AUTOSAR XML (schema 4-1-3)
standard types defined: boolean, sint8, uint16, uint32, uint8, boolean_CompuMethod, boolean_DataConstr, sint8_DataConstr, uint16_DataConstr, uint32_DataConstr, uint8_DataConstr, sint16
package /ComponentTypes/DataTypeMappingSets
  data type mapping set DTMS_CabinT_DD
    data-type-maps:
      application-data-type=Appl_CabinT_tTrfReSnsr_CUR, implementation-data-type=CabinT_tTrfReSnsr_CUR_Type
      application-data-type=Appl_CabinT_tTrfSnsr_CUR, implementation-data-type=CabinT_tTrfSnsr_CUR_Type
      application-data-type=T_q0p1_o273p14_DegC_s16, implementation-data-type=sint16
      application-data-type=U_q1_mV_u16, implementation-data-type=ImplementationDataTypes/uint16
package /MICROSAR/Dem_swc/DataTypes
  5 x impl type:
    Dem_DebounceResetStatusType: compu {0=DEM_DEBOUNCE_STATUS_FREEZE, 1=DEM_DEBOUNCE_STATUS_RESET}, range raw 0..255, implementation-data-type=ImplementationDataTypes/uint8
    Dem_DTCFormatType: compu {0=DEM_DTC_FORMAT_OBD, 1=DEM_DTC_FORMAT_UDS, 2=DEM_DTC_FORMAT_J1939}, range raw 0..2, implementation-data-type=ImplementationDataTypes/uint8
    Dem_EventStatusType:
      compu {0=DEM_EVENT_STATUS_PASSED, 1=DEM_EVENT_STATUS_FAILED, 2=DEM_EVENT_STATUS_PREPASSED, 3=DEM_EVENT_STATUS_PREFAILED, 4=DEM_EVENT_STATUS_FDC_THRESHOLD_REACHED, 5=DEM_EVENT_STATUS_PASSED_CONDITIONS_NOT_FULFILLED, 6=DEM_EVENT_STATUS_FAILED_CONDITIONS_NOT_FULFILLED, 7=DEM_EVENT_STATUS_PREPASSED_CONDITIONS_NOT_FULFILLED, 8=DEM_EVENT_STATUS_PREFAILED_CONDITIONS_NOT_FULFILLED}
      range raw 0..255
      implementation-data-type=ImplementationDataTypes/uint8
    Dem_MaxDataValueType: category=ARRAY, sw-calibration-access=READ-ONLY
      element Dem_MaxDataValueTypeElement: array-size=40, array-size-semantics=FIXED-SIZE, implementation-data-type=ImplementationDataTypes/uint8
    Dem_UdsStatusByteType:
      compu {mask 1: 1=DEM_UDS_STATUS_TF (bit 0: TestFailed), mask 2: 2=DEM_UDS_STATUS_TFTOC (bit 1: TestFailedThisOperationCycle), mask 4: 4=DEM_UDS_STATUS_PDTC (bit 2: PendingDTC), mask 8: 8=DEM_UDS_STATUS_CDTC (bit 3: ConfirmedDTC), mask 16: 16=DEM_UDS_STATUS_TNCSLC (bit 4: TestNotCompletedSinceLastClear), mask 32: 32=DEM_UDS_STATUS_TFSLC (bit 5: TestFailedSinceLastClear), mask 64: 64=DEM_UDS_STATUS_TNCTOC (bit 6: TestNotCompletedThisOperationCycle), mask 128: 128=DEM_UDS_STATUS_WIR (bit 7: WarningIndicatorRequested)}
      range raw 0..255
      implementation-data-type=ImplementationDataTypes/uint8
package /MICROSAR/Dem_swc/Interfaces
  client server interface DiagnosticMonitor: is-service=true, service-kind=DIAGNOSTIC-EVENT-MANAGER
    11 x operation:
      GetDTCOfEvent: possible-error=[DEM_E_NO_DTC_AVAILABLE, DiagnosticMonitor/E_NOT_OK]
        arg DTCFormat: type=Dem_DTCFormatType, direction=IN, server-argument-impl-policy=USE-ARGUMENT-TYPE
        arg DTCOfEvent: type=uint32, direction=OUT, server-argument-impl-policy=USE-ARGUMENT-TYPE
      GetEventExtendedDataRecordEx: possible-error=[DEM_BUFFER_TOO_SMALL, DEM_NO_SUCH_ELEMENT, DiagnosticMonitor/E_NOT_OK]
        arg RecordNumber: type=ImplementationDataTypes/uint8, direction=IN, server-argument-impl-policy=USE-ARGUMENT-TYPE
        arg DestBuffer: type=Dem_MaxDataValueType, direction=OUT, server-argument-impl-policy=USE-ARGUMENT-TYPE
        arg BufSize: type=ImplementationDataTypes/uint16, direction=INOUT, server-argument-impl-policy=USE-ARGUMENT-TYPE
      GetEventFailed: possible-error=DiagnosticMonitor/E_NOT_OK
        arg EventFailed: type=ImplementationDataTypes/boolean, direction=OUT, server-argument-impl-policy=USE-ARGUMENT-TYPE
      GetEventFreezeFrameDataEx: possible-error=[DEM_BUFFER_TOO_SMALL, DEM_NO_SUCH_ELEMENT, DiagnosticMonitor/E_NOT_OK]
        4 x arg, all with server-argument-impl-policy=USE-ARGUMENT-TYPE:
          RecordNumber: type=ImplementationDataTypes/uint8, direction=IN
          DataId: type=ImplementationDataTypes/uint16, direction=IN
          DestBuffer: type=Dem_MaxDataValueType, direction=OUT
          BufSize: type=ImplementationDataTypes/uint16, direction=INOUT
      GetEventStatus: possible-error=DiagnosticMonitor/E_NOT_OK
        arg UDSStatusByte: type=Dem_UdsStatusByteType, direction=OUT, server-argument-impl-policy=USE-ARGUMENT-TYPE
      GetEventTested: possible-error=DiagnosticMonitor/E_NOT_OK
        arg EventTested: type=ImplementationDataTypes/boolean, direction=OUT, server-argument-impl-policy=USE-ARGUMENT-TYPE
      GetEventUdsStatus: possible-error=DiagnosticMonitor/E_NOT_OK
        arg UDSStatusByte: type=Dem_UdsStatusByteType, direction=OUT, server-argument-impl-policy=USE-ARGUMENT-TYPE
      GetFaultDetectionCounter: possible-error=[DEM_E_NO_FDC_AVAILABLE, DiagnosticMonitor/E_NOT_OK]
        arg FaultDetectionCounter: type=sint8, direction=OUT, server-argument-impl-policy=USE-ARGUMENT-TYPE
      ResetEventDebounceStatus: possible-error=DiagnosticMonitor/E_NOT_OK
        arg DebounceResetStatus: type=Dem_DebounceResetStatusType, direction=IN, server-argument-impl-policy=USE-ARGUMENT-TYPE
      ResetEventStatus: possible-error=DiagnosticMonitor/E_NOT_OK
      SetEventStatus: possible-error=DiagnosticMonitor/E_NOT_OK
        arg EventStatus: type=Dem_EventStatusType, direction=IN, server-argument-impl-policy=USE-ARGUMENT-TYPE
    5 x error:
      DEM_BUFFER_TOO_SMALL: error-code=21
      DEM_E_NO_DTC_AVAILABLE: error-code=10
      DEM_E_NO_FDC_AVAILABLE: error-code=14
      DEM_NO_SUCH_ELEMENT: error-code=48
      E_NOT_OK: error-code=1
package /UAES/ASW/ApplicationDataTypes
  4 x app type, all with sw-calibration-access=READ-WRITE:
    Appl_CabinT_tTrfReSnsr_CUR: category=CURVE, sw-calprm-axis-set={sw-axis-index=1, category=COM_AXIS, sw-axis-individual={compu {phys=raw for raw -INF..INF; unit mV}, sw-max-axis-points=30, sw-min-axis-points=30, range phys 0..65535, raw 0..65535}}, compu {phys=raw*0.1-273.14 for raw -INF..INF; unit DegC}, range raw -32768..32767
    Appl_CabinT_tTrfSnsr_CUR: category=CURVE, sw-calprm-axis-set={sw-axis-index=1, category=COM_AXIS, sw-axis-individual={compu {phys=raw for raw -INF..INF; unit mV}, sw-max-axis-points=30, sw-min-axis-points=30, range phys 0..65535, raw 0..65535}}, compu {phys=raw*0.1-273.14 for raw -INF..INF; unit DegC}, range raw -32768..32767
    T_q0p1_o273p14_DegC_s16: category=VALUE, compu {phys=raw*0.1-273.14 for raw -INF..INF; unit DegC}, range raw -32768..32767
    U_q1_mV_u16: category=VALUE, compu {phys=raw for raw -INF..INF; unit mV}, range phys 0..65535, raw 0..65535
package /UAES/ASW/CompuMethods
  compu method CM_boolean: 0=FALSE, 1=TRUE
package /UAES/ASW/DataConstrs
  range DC_boolean: raw 0..1
  range DC_sint16: raw -32768..32767
  range DC_uint16: phys 0..6553.5, raw 0..65535
  range DC_uint8: raw 0..255
package /UAES/ASW/ImplementationDataTypes
  6 x impl type:
    CabinT_tTrfReSnsr_CUR_Type: category=STRUCTURE
      element N1: implementation-data-type=ImplementationDataTypes/uint16
      element BP1: implementation-data-type=rt_Array_U_q1_mV_u16_30
      element Table: implementation-data-type=rt_Array_T_q0p1_o273p14_DegC_s16_30
    CabinT_tTrfSnsr_CUR_Type: category=STRUCTURE
      element N1: implementation-data-type=ImplementationDataTypes/uint16
      element BP1: implementation-data-type=rt_Array_U_q1_mV_u16_30
      element Table: implementation-data-type=rt_Array_T_q0p1_o273p14_DegC_s16_30
    rt_Array_T_q0p1_o273p14_DegC_s16_30: category=ARRAY
      element rt_Array_T_q0p1_o273p14_DegC_s16_30: array-size=30, array-size-semantics=FIXED-SIZE, implementation-data-type=T_q0p1_o273p14_DegC_s16
    rt_Array_U_q1_mV_u16_30: category=ARRAY
      element rt_Array_U_q1_mV_u16_30: array-size=30, array-size-semantics=FIXED-SIZE, implementation-data-type=U_q1_mV_u16
    T_q0p1_o273p14_DegC_s16: category=VALUE, base-type=sint16, range raw -32768..32767
    U_q1_mV_u16: category=VALUE, base-type=BaseTypes/uint16, range phys 0..65535, raw 0..65535
package /UAES/ASW/ImplementationDataTypes/Ground
  10 x constant specification:
    CabinT_numRawVoltFildPoint_C: value-spec=CabinT_numRawVoltFildPoint_C:3
    CabinT_numReRawVoltFildPoint_C: value-spec=CabinT_numRawVoltFildPoint_C:3
    CabinT_tDfl_C: value-spec=25.060000000000002 DegC
    CabinT_tReDfl_C: value-spec=25.060000000000002 DegC
    CabinT_tTrfReSnsr_CUR: value-spec=fields=[N:30, X:[546, 618, 699, 793, 898, 1018, 1153, 1297, 1452, 1644, 1853, 2077, 2201, 2315, 2445, 2562, 2695, 2815, 2949, 3067, 3315, 3552, 3774, 3977, 4160, 4320, 4457, 4573, 4668, 4746], Y:[3581, 3531, 3481, 3431, 3381, 3331, 3281, 3231, 3181, 3131, 3081, 3031, 3006, 2981, 2956, 2931, 2906, 2881, 2856, 2831, 2781, 2731, 2681, 2631, 2581, 2531, 2481, 2431, 2381, 2331]]
    CabinT_tTrfSnsr_CUR: value-spec=fields=[N:30, X:[326, 374, 427, 491, 563, 650, 743, 857, 986, 1132, 1298, 1485, 1592, 1692, 1810, 1920, 2048, 2165, 2302, 2425, 2694, 2966, 3236, 3497, 3740, 3964, 4162, 4334, 4479, 4601], Y:[3581, 3531, 3481, 3431, 3381, 3331, 3281, 3231, 3181, 3131, 3081, 3031, 3006, 2981, 2956, 2931, 2906, 2881, 2856, 2831, 2781, 2731, 2681, 2631, 2581, 2531, 2481, 2431, 2381, 2331]]
    CabinT_uRawMaxSRC_C: value-spec=4930 mV
    CabinT_uRawMinSRC_C: value-spec=68 mV
    CabinT_uRawReMaxSRC_C: value-spec=4930 mV
    CabinT_uRawReMinSRC_C: value-spec=68 mV
package /UAES/ASW/PortInterfaces
  client server interface IoHwAb_IoSigAdc
    operation Adc_Get: possible-error=IoHwAb_IoSigAdc/E_NOT_OK
      arg id_u16: type=ImplementationDataTypes/uint16, direction=IN, server-argument-impl-policy=USE-ARGUMENT-TYPE
      arg val_s16: type=sint16, direction=OUT, server-argument-impl-policy=USE-ARGUMENT-TYPE
    operation AdcFac_Get: possible-error=IoHwAb_IoSigAdc/E_NOT_OK
      arg id_u16: type=ImplementationDataTypes/uint16, direction=IN, server-argument-impl-policy=USE-ARGUMENT-TYPE
      arg val_s16: type=sint16, direction=OUT, server-argument-impl-policy=USE-ARGUMENT-TYPE
    operation AdcVRMBatt_Get: possible-error=IoHwAb_IoSigAdc/E_NOT_OK
      arg id_u16: type=ImplementationDataTypes/uint16, direction=IN, server-argument-impl-policy=USE-ARGUMENT-TYPE
      arg val_u8: type=ImplementationDataTypes/uint8, direction=OUT, server-argument-impl-policy=USE-ARGUMENT-TYPE
    error E_NOT_OK: error-code=1
  8 x sender receiver interface:
    BattU_bVoltEnbPinDiag: invalidation-policy{data-element=BattU_bVoltEnbPinDiag/Val, handle-invalid=DONT-INVALIDATE}
      data Val: sw-calibration-access=READ-ONLY, type=ImplementationDataTypes/boolean
    CabinT_t: invalidation-policy{data-element=CabinT_t/Val, handle-invalid=DONT-INVALIDATE}
      data Val: sw-calibration-access=READ-ONLY, type=T_q0p1_o273p14_DegC_s16
    CabinT_tRe: invalidation-policy{data-element=CabinT_tRe/Val, handle-invalid=DONT-INVALIDATE}
      data Val: sw-calibration-access=READ-ONLY, type=T_q0p1_o273p14_DegC_s16
    CabinT_uRaw: invalidation-policy{data-element=CabinT_uRaw/Val, handle-invalid=DONT-INVALIDATE}
      data Val: sw-calibration-access=READ-ONLY, type=U_q1_mV_u16
    CabinT_uRawRe: invalidation-policy{data-element=CabinT_uRawRe/Val, handle-invalid=DONT-INVALIDATE}
      data Val: sw-calibration-access=READ-ONLY, type=U_q1_mV_u16
    gCFG_bCabinTSnsrAvl: invalidation-policy{data-element=gCFG_bCabinTSnsrAvl/Val, handle-invalid=DONT-INVALIDATE}
      data Val: sw-calibration-access=READ-ONLY, type=ImplementationDataTypes/boolean
    gCFG_bReCabinTSnsrAvl: invalidation-policy{data-element=gCFG_bReCabinTSnsrAvl/Val, handle-invalid=DONT-INVALIDATE}
      data Val: sw-calibration-access=READ-ONLY, type=ImplementationDataTypes/boolean
    VehCoorn_stPwrMod: invalidation-policy{data-element=VehCoorn_stPwrMod/Val, handle-invalid=DONT-INVALIDATE}
      data Val: sw-calibration-access=READ-ONLY, type=ImplementationDataTypes/uint8
package /UAES/ASW/SwAddrMethods
  sw addr method CALDATA
package /UAES/ASW/SwComponentTypes
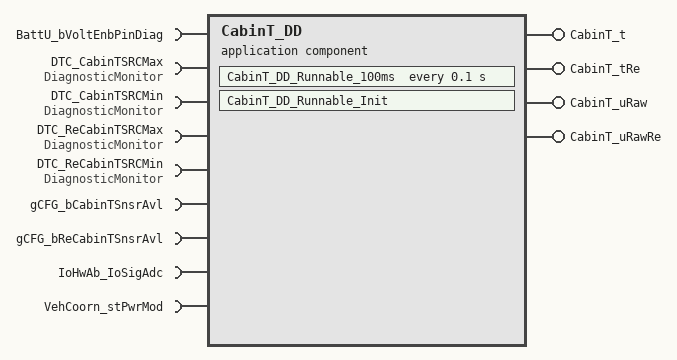
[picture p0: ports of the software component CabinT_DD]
  application sw component type CabinT_DD
    4 x provide port:
      CabinT_t: nonqueued-sender-com-spec{data-element=CabinT_t/Val, init-value=0}, provided-interface=CabinT_t
      CabinT_tRe: nonqueued-sender-com-spec{data-element=CabinT_tRe/Val, init-value=0}, provided-interface=CabinT_tRe
      CabinT_uRaw: nonqueued-sender-com-spec{data-element=CabinT_uRaw/Val, init-value=0}, provided-interface=CabinT_uRaw
      CabinT_uRawRe: nonqueued-sender-com-spec{data-element=CabinT_uRawRe/Val, init-value=0}, provided-interface=CabinT_uRawRe
    9 x require port:
      BattU_bVoltEnbPinDiag: nonqueued-receiver-com-spec{data-element=BattU_bVoltEnbPinDiag/Val, filter=data-filter-type=ALWAYS, init-value=0}, required-interface=BattU_bVoltEnbPinDiag
      DTC_CabinTSRCMax: required-interface=DiagnosticMonitor
        required-com-specs:
          GetDTCOfEvent
          GetEventExtendedDataRecordEx
          GetEventFailed
          GetEventFreezeFrameDataEx
          GetEventStatus
          GetEventTested
          GetEventUdsStatus
          GetFaultDetectionCounter
          ResetEventDebounceStatus
          ResetEventStatus
          SetEventStatus
      DTC_CabinTSRCMin: required-interface=DiagnosticMonitor
        required-com-specs:
          GetDTCOfEvent
          GetEventExtendedDataRecordEx
          GetEventFailed
          GetEventFreezeFrameDataEx
          GetEventStatus
          GetEventTested
          GetEventUdsStatus
          GetFaultDetectionCounter
          ResetEventDebounceStatus
          ResetEventStatus
          SetEventStatus
      DTC_ReCabinTSRCMax: required-interface=DiagnosticMonitor
        required-com-specs:
          GetDTCOfEvent
          GetEventExtendedDataRecordEx
          GetEventFailed
          GetEventFreezeFrameDataEx
          GetEventStatus
          GetEventTested
          GetEventUdsStatus
          GetFaultDetectionCounter
          ResetEventDebounceStatus
          ResetEventStatus
          SetEventStatus
      DTC_ReCabinTSRCMin: required-interface=DiagnosticMonitor
        required-com-specs:
          GetDTCOfEvent
          GetEventExtendedDataRecordEx
          GetEventFailed
          GetEventFreezeFrameDataEx
          GetEventStatus
          GetEventTested
          GetEventUdsStatus
          GetFaultDetectionCounter
          ResetEventDebounceStatus
          ResetEventStatus
          SetEventStatus
      gCFG_bCabinTSnsrAvl: nonqueued-receiver-com-spec{data-element=gCFG_bCabinTSnsrAvl/Val, filter=data-filter-type=ALWAYS, init-value=0}, required-interface=gCFG_bCabinTSnsrAvl
      gCFG_bReCabinTSnsrAvl: nonqueued-receiver-com-spec{data-element=gCFG_bReCabinTSnsrAvl/Val, filter=data-filter-type=ALWAYS, init-value=0}, required-interface=gCFG_bReCabinTSnsrAvl
      IoHwAb_IoSigAdc: required-com-specs=[Adc_Get, AdcFac_Get, AdcVRMBatt_Get], required-interface=IoHwAb_IoSigAdc
      VehCoorn_stPwrMod: nonqueued-receiver-com-spec{data-element=VehCoorn_stPwrMod/Val, filter=data-filter-type=ALWAYS, init-value=0}, required-interface=VehCoorn_stPwrMod
    behavior CabinT_DD_InternalBehavior: data-type-mapping=DTMS_CabinT_DD
      timing event TMT_CabinT_DD_Runnable_100ms: start-on-event=CabinT_DD_Runnable_100ms, period=0.1
      init event CabinT_DD_InitEvent: start-on-event=CabinT_DD_Runnable_Init
      runnable CabinT_DD_Runnable_100ms
        data-receive-point-by-arguments:
          4 x access:
            REC_BattU_bVoltEnbPinDiag_Val: accessed-variable=BattU_bVoltEnbPinDiag.Val
            REC_gCFG_bCabinTSnsrAvl_Val: accessed-variable=gCFG_bCabinTSnsrAvl.Val
            REC_gCFG_bReCabinTSnsrAvl_Val: accessed-variable=gCFG_bReCabinTSnsrAvl.Val
            REC_VehCoorn_stPwrMod_Val: accessed-variable=VehCoorn_stPwrMod.Val
        data-send-points:
          4 x access:
            SEND_CabinT_t_Val: accessed-variable=CabinT_t.Val
            SEND_CabinT_tRe_Val: accessed-variable=CabinT_tRe.Val
            SEND_CabinT_uRaw_Val: accessed-variable=CabinT_uRaw.Val
            SEND_CabinT_uRawRe_Val: accessed-variable=CabinT_uRawRe.Val
        10 x parameter access:
          PA_CabinT_numRawVoltFildPoint_C: accessed-parameter=CabinT_numRawVoltFildPoint_C
          PA_CabinT_numReRawVoltFildPoint_C: accessed-parameter=CabinT_numReRawVoltFildPoint_C
          PA_CabinT_tDfl_C: accessed-parameter=CabinT_tDfl_C
          PA_CabinT_tReDfl_C: accessed-parameter=CabinT_tReDfl_C
          PA_CabinT_tTrfReSnsr_CUR: accessed-parameter=CabinT_tTrfReSnsr_CUR
          PA_CabinT_tTrfSnsr_CUR: accessed-parameter=CabinT_tTrfSnsr_CUR
          PA_CabinT_uRawMaxSRC_C: accessed-parameter=CabinT_uRawMaxSRC_C
          PA_CabinT_uRawMinSRC_C: accessed-parameter=CabinT_uRawMinSRC_C
          PA_CabinT_uRawReMaxSRC_C: accessed-parameter=CabinT_uRawReMaxSRC_C
          PA_CabinT_uRawReMinSRC_C: accessed-parameter=CabinT_uRawReMinSRC_C
        17 x sync call:
          SC_DTC_CabinTSRCMax_GetEventFailed: operation=DTC_CabinTSRCMax.GetEventFailed, timeout=1E-06
          SC_DTC_CabinTSRCMax_GetEventTested: operation=DTC_CabinTSRCMax.GetEventTested, timeout=1E-06
          SC_DTC_CabinTSRCMax_ResetEventDebounceStatus: operation=DTC_CabinTSRCMax.ResetEventDebounceStatus, timeout=1E-06
          SC_DTC_CabinTSRCMax_SetEventStatus: operation=DTC_CabinTSRCMax.SetEventStatus, timeout=1E-06
          SC_DTC_CabinTSRCMin_GetEventFailed: operation=DTC_CabinTSRCMin.GetEventFailed, timeout=1E-06
          SC_DTC_CabinTSRCMin_GetEventTested: operation=DTC_CabinTSRCMin.GetEventTested, timeout=1E-06
          SC_DTC_CabinTSRCMin_ResetEventDebounceStatus: operation=DTC_CabinTSRCMin.ResetEventDebounceStatus, timeout=1E-06
          SC_DTC_CabinTSRCMin_SetEventStatus: operation=DTC_CabinTSRCMin.SetEventStatus, timeout=1E-06
          SC_DTC_ReCabinTSRCMax_GetEventFailed: operation=DTC_ReCabinTSRCMax.GetEventFailed, timeout=1E-06
          SC_DTC_ReCabinTSRCMax_GetEventTested: operation=DTC_ReCabinTSRCMax.GetEventTested, timeout=1E-06
          SC_DTC_ReCabinTSRCMax_ResetEventDebounceStatus: operation=DTC_ReCabinTSRCMax.ResetEventDebounceStatus, timeout=1E-06
          SC_DTC_ReCabinTSRCMax_SetEventStatus: operation=DTC_ReCabinTSRCMax.SetEventStatus, timeout=1E-06
          SC_DTC_ReCabinTSRCMin_GetEventFailed: operation=DTC_ReCabinTSRCMin.GetEventFailed, timeout=1E-06
          SC_DTC_ReCabinTSRCMin_GetEventStatus: operation=DTC_ReCabinTSRCMin.GetEventStatus, timeout=1E-06
          SC_DTC_ReCabinTSRCMin_ResetEventDebounceStatus: operation=DTC_ReCabinTSRCMin.ResetEventDebounceStatus, timeout=1E-06
          SC_DTC_ReCabinTSRCMin_SetEventStatus: operation=DTC_ReCabinTSRCMin.SetEventStatus, timeout=1E-06
          SC_IoHwAb_IoSigAdc_AdcFac_Get: operation=IoHwAb_IoSigAdc.AdcFac_Get, timeout=0
      runnable CabinT_DD_Runnable_Init
        data-receive-point-by-arguments:
          4 x access:
            REC_BattU_bVoltEnbPinDiag_Val: accessed-variable=BattU_bVoltEnbPinDiag.Val
            REC_gCFG_bCabinTSnsrAvl_Val: accessed-variable=gCFG_bCabinTSnsrAvl.Val
            REC_gCFG_bReCabinTSnsrAvl_Val: accessed-variable=gCFG_bReCabinTSnsrAvl.Val
            REC_VehCoorn_stPwrMod_Val: accessed-variable=VehCoorn_stPwrMod.Val
        data-send-points:
          4 x access:
            SEND_CabinT_t_Val: accessed-variable=CabinT_t.Val
            SEND_CabinT_tRe_Val: accessed-variable=CabinT_tRe.Val
            SEND_CabinT_uRaw_Val: accessed-variable=CabinT_uRaw.Val
            SEND_CabinT_uRawRe_Val: accessed-variable=CabinT_uRawRe.Val
        10 x parameter access:
          PA_CabinT_numRawVoltFildPoint_C: accessed-parameter=CabinT_numRawVoltFildPoint_C
          PA_CabinT_numReRawVoltFildPoint_C: accessed-parameter=CabinT_numReRawVoltFildPoint_C
          PA_CabinT_tDfl_C: accessed-parameter=CabinT_tDfl_C
          PA_CabinT_tReDfl_C: accessed-parameter=CabinT_tReDfl_C
          PA_CabinT_tTrfReSnsr_CUR: accessed-parameter=CabinT_tTrfReSnsr_CUR
          PA_CabinT_tTrfSnsr_CUR: accessed-parameter=CabinT_tTrfSnsr_CUR
          PA_CabinT_uRawMaxSRC_C: accessed-parameter=CabinT_uRawMaxSRC_C
          PA_CabinT_uRawMinSRC_C: accessed-parameter=CabinT_uRawMinSRC_C
          PA_CabinT_uRawReMaxSRC_C: accessed-parameter=CabinT_uRawReMaxSRC_C
          PA_CabinT_uRawReMinSRC_C: accessed-parameter=CabinT_uRawReMinSRC_C
        sync call SC_IoHwAb_IoSigAdc_AdcFac_Get: operation=IoHwAb_IoSigAdc.AdcFac_Get, timeout=0
      shared-parameters:
        10 x parameter data prototype, all with sw-addr-method=CALDATA, sw-calibration-access=READ-WRITE:
          CabinT_numRawVoltFildPoint_C: type=ImplementationDataTypes/uint8, init-value=constant-reference={short-label=CabinT_numRawVoltFildPoint_C, constant=CabinT_numRawVoltFildPoint_C}
          CabinT_numReRawVoltFildPoint_C: type=ImplementationDataTypes/uint8, init-value=constant-reference={short-label=CabinT_numRawVoltFildPoint_C, constant=CabinT_numReRawVoltFildPoint_C}
          CabinT_tDfl_C: type=T_q0p1_o273p14_DegC_s16, init-value=constant-reference={short-label=CabinT_tDfl_C, constant=CabinT_tDfl_C}
          CabinT_tReDfl_C: type=T_q0p1_o273p14_DegC_s16, init-value=constant-reference={short-label=CabinT_tDfl_C, constant=CabinT_tReDfl_C}
          CabinT_tTrfReSnsr_CUR: type=Appl_CabinT_tTrfReSnsr_CUR, init-value=constant-reference={short-label=CabinT_tTrfSnsr_CUR, constant=CabinT_tTrfReSnsr_CUR}
          CabinT_tTrfSnsr_CUR: type=Appl_CabinT_tTrfSnsr_CUR, init-value=constant-reference={short-label=CabinT_tTrfSnsr_CUR, constant=CabinT_tTrfSnsr_CUR}
          CabinT_uRawMaxSRC_C: type=U_q1_mV_u16, init-value=constant-reference={short-label=CabinT_uRawMaxSRC_C, constant=CabinT_uRawMaxSRC_C}
          CabinT_uRawMinSRC_C: type=U_q1_mV_u16, init-value=constant-reference={short-label=CabinT_uRawMinSRC_C, constant=CabinT_uRawMinSRC_C}
          CabinT_uRawReMaxSRC_C: type=U_q1_mV_u16, init-value=constant-reference={short-label=CabinT_uRawMaxSRC_C, constant=CabinT_uRawReMaxSRC_C}
          CabinT_uRawReMinSRC_C: type=U_q1_mV_u16, init-value=constant-reference={short-label=CabinT_uRawMinSRC_C, constant=CabinT_uRawReMinSRC_C}
  swc implementation CabinT_DD_Implementation: behavior=CabinT_DD_InternalBehavior
    code-descriptors:
      code Default: artifact-descriptors=autosar-engineering-object={short-label=Default, category=SWSRC}
package /UAES/ASW/Units
  unit DegC: display-name=DegC, factor-si-to-unit=1, offset-si-to-unit=0
  unit mV: display-name=mV, factor-si-to-unit=1, offset-si-to-unit=0
  unit NoUnit: factor-si-to-unit=1, offset-si-to-unit=0
